AUTOSAR XML (schema 00046)
package /ComponentTypes
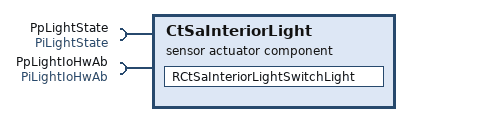
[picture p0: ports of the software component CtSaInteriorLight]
  sensor actuator sw component type CtSaInteriorLight
    require port PpLightState: nonqueued-receiver-com-spec{data-element=DeLightState, init-value=constant-reference=CLightOff}, required-interface=PiLightState
    require port PpLightIoHwAb: client-com-spec=WriteChannel, required-interface=PiLightIoHwAb
    behavior CtSaInteriorLight_InternalBehavior: data-type-mapping=DemoTypeMapping, supports-multiple-instantiation=true
      data received event DRT_RCtSaInteriorLightSwitchLight_PpLightState_DeLightState: start-on-event=RCtSaInteriorLightSwitchLight, data=PpLightState.DeLightState
      runnable RCtSaInteriorLightSwitchLight
        data-receive-point-by-arguments:
          access REC_PpLightState_DeLightState: accessed-variable=PpLightState.DeLightState
  swc implementation CtSaInteriorLight_Implementation: behavior=CtSaInteriorLight_InternalBehavior
